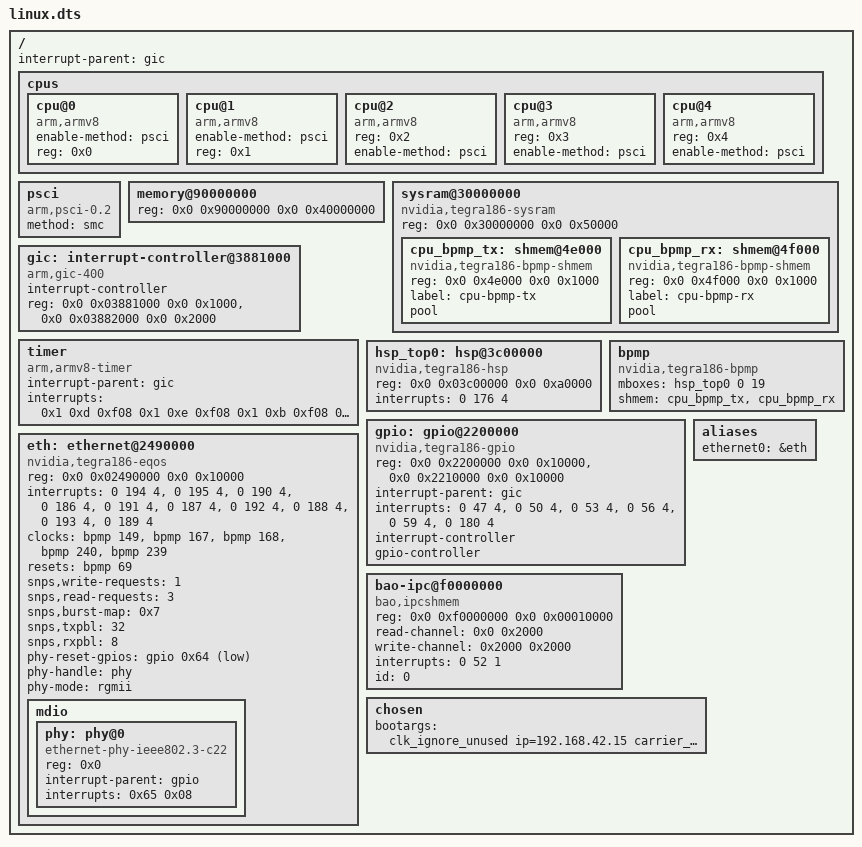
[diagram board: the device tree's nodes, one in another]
/dts-v1/;

/ {
	#address-cells = <2>;
	#size-cells = <2>;
	interrupt-parent = <&gic>;

	cpus {
		#size-cells = <0x0>;
		#address-cells = <0x1>;

		cpu@0 {
			compatible = "arm,armv8";
			device_type = "cpu";
			enable-method = "psci";
			reg = <0x0>;
		};

		cpu@1 {
			compatible = "arm,armv8";
			device_type = "cpu";
			enable-method = "psci";
			reg = <0x1>;
		};

		cpu@2 {
			reg = <0x2>;
			compatible = "arm,armv8";
			device_type = "cpu";
			enable-method = "psci";
		};

		cpu@3 {
			reg = <0x3>;
			compatible = "arm,armv8";
			device_type = "cpu";
			enable-method = "psci";
		};


		cpu@4 {
			reg = <0x4>;
			compatible = "arm,armv8";
			device_type = "cpu";
			enable-method = "psci";
		};

	};

	psci {
		compatible = "arm,psci-0.2";
		method = "smc";
	};

	memory@90000000 {
		reg = <0x0 0x90000000 0x0 0x40000000>;
		device_type = "memory";
	};

	sysram@30000000 {
		compatible = "nvidia,tegra186-sysram", "mmio-sram";
		reg = <0x0 0x30000000 0x0 0x50000>;
		#address-cells = <2>;
		#size-cells = <2>;
		ranges = <0 0x0 0x0 0x30000000 0x0 0x50000>;

		cpu_bpmp_tx: shmem@4e000 {
			compatible = "nvidia,tegra186-bpmp-shmem";
			reg = <0x0 0x4e000 0x0 0x1000>;
			label = "cpu-bpmp-tx";
			pool;
		};

		cpu_bpmp_rx: shmem@4f000 {
			compatible = "nvidia,tegra186-bpmp-shmem";
			reg = <0x0 0x4f000 0x0 0x1000>;
			label = "cpu-bpmp-rx";
			pool;
		};
	};

	gic: interrupt-controller@3881000 {
		compatible = "arm,gic-400";
		#interrupt-cells = <3>;
		interrupt-controller;
		reg = <0x0 0x03881000 0x0 0x1000>,
		      <0x0 0x03882000 0x0 0x2000>;
	};

   	timer {
		compatible = "arm,armv8-timer";
		interrupt-parent = <&gic>;
		interrupts = <0x1 0xd 0xf08 0x1 0xe 0xf08 0x1 0xb 0xf08 0x1 0xa 0xf08>;
	};

	hsp_top0: hsp@3c00000 {
		compatible = "nvidia,tegra186-hsp";
		reg = <0x0 0x03c00000 0x0 0xa0000>;
		interrupts = <0 176 4>;
		interrupt-names = "doorbell";
		#mbox-cells = <2>;
		status = "okay";
	};

	bpmp: bpmp {
		compatible = "nvidia,tegra186-bpmp";
		mboxes = <&hsp_top0 0 19>;
		shmem = <&cpu_bpmp_tx &cpu_bpmp_rx>;
		#clock-cells = <1>;
		#reset-cells = <1>;
		#power-domain-cells = <1>;
	};

	gpio: gpio@2200000 {
		compatible = "nvidia,tegra186-gpio";
		reg-names = "security", "gpio";
		reg = <0x0 0x2200000 0x0 0x10000>,
		      <0x0 0x2210000 0x0 0x10000>;
		interrupt-parent = <&gic>;
		interrupts = <0  47 4>,
			     <0  50 4>,
			     <0  53 4>,
			     <0  56 4>,
			     <0  59 4>,
			     <0 180 4>;
		#interrupt-cells = <2>;
		interrupt-controller;
		#gpio-cells = <2>;
		gpio-controller;
	};

	eth: ethernet@2490000 {
		compatible = "nvidia,tegra186-eqos",
			     "snps,dwc-qos-ethernet-4.10";
		reg = <0x0 0x02490000 0x0 0x10000>;
		interrupts = <0 194 4>, /* common */
			     <0 195 4>, /* power */
			     <0 190 4>, /* rx0 */
			     <0 186 4>, /* tx0 */
			     <0 191 4>, /* rx1 */
			     <0 187 4>, /* tx1 */
			     <0 192 4>, /* rx2 */
			     <0 188 4>, /* tx2 */
			     <0 193 4>, /* rx3 */
			     <0 189 4>; /* tx3 */
		clocks = <&bpmp 149>,
			 <&bpmp 167>,
			 <&bpmp 168>,
			 <&bpmp 240>,
			 <&bpmp 239>;
		clock-names = "master_bus", "slave_bus", "rx", "tx", "ptp_ref";
		resets = <&bpmp 69>;
		reset-names = "eqos";

		snps,write-requests = <1>;
		snps,read-requests = <3>;
		snps,burst-map = <0x7>;
		snps,txpbl = <32>;
		snps,rxpbl = <8>;

		status = "okay";

		phy-reset-gpios = <&gpio 0x64 0x1>;
		phy-handle = <&phy>;
		phy-mode = "rgmii";

		mdio {
			#address-cells = <1>;
			#size-cells = <0>;	

			phy: phy@0 {
				compatible = "ethernet-phy-ieee802.3-c22";
				reg = <0x0>;
				interrupt-parent = <&gpio>;
				interrupts = <0x65 0x08>;
				#phy-cells = <0>;
			};
		};
	};

    bao-ipc@f0000000 {
        compatible = "bao,ipcshmem";
        reg = <0x0 0xf0000000 0x0 0x00010000>;
		read-channel = <0x0 0x2000>;
		write-channel = <0x2000 0x2000>;
        interrupts = <0 52 1>;
		id = <0>;
    };

	aliases {
		ethernet0 = &eth;
	};

	chosen {
		bootargs = "clk_ignore_unused ip=192.168.42.15 carrier_timeout=0";
	};

};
